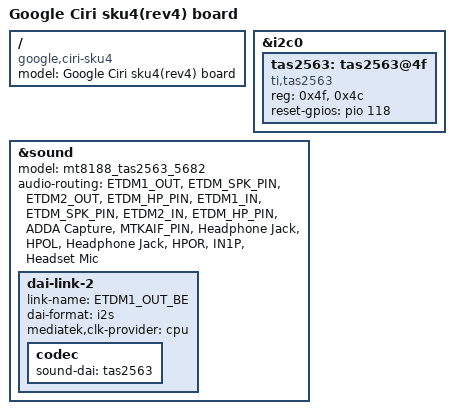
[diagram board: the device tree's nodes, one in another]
// SPDX-License-Identifier: (GPL-2.0 OR MIT)
/*
 * Copyright 2024 Google LLC
 */
/dts-v1/;
#include "mt8188-geralt-ciri.dtsi"
#include "mt8188-ciri-camera-v4l2.dtsi"

/delete-node/ &max98390_38;
/delete-node/ &max98390_39;

/ {
	model = "Google Ciri sku4(rev4) board";
	compatible = "google,ciri-sku4", "google,ciri", "mediatek,mt8188";
};

&i2c0 {
	tas2563: tas2563@4f {
		#sound-dai-cells = <0>;
		compatible = "ti,tas2563";
		reg = <0x4f>, /* left-channel */
			  <0x4c>; /* right-channel */
		reset-gpios = <&pio 118 GPIO_ACTIVE_HIGH>;
		status = "okay";
     };
};

&sound {
	model = "mt8188_tas2563_5682";
	audio-routing =
		"ETDM1_OUT", "ETDM_SPK_PIN",
		"ETDM2_OUT", "ETDM_HP_PIN",
		"ETDM1_IN", "ETDM_SPK_PIN",
		"ETDM2_IN", "ETDM_HP_PIN",
		"ADDA Capture", "MTKAIF_PIN",
		"Headphone Jack", "HPOL",
		"Headphone Jack", "HPOR",
		"IN1P", "Headset Mic";
	status = "okay";

	dai-link-2 {
		link-name = "ETDM1_OUT_BE";
		dai-format = "i2s";
		mediatek,clk-provider = "cpu";
		codec {
			sound-dai = <&tas2563>;
		};
	};
};
